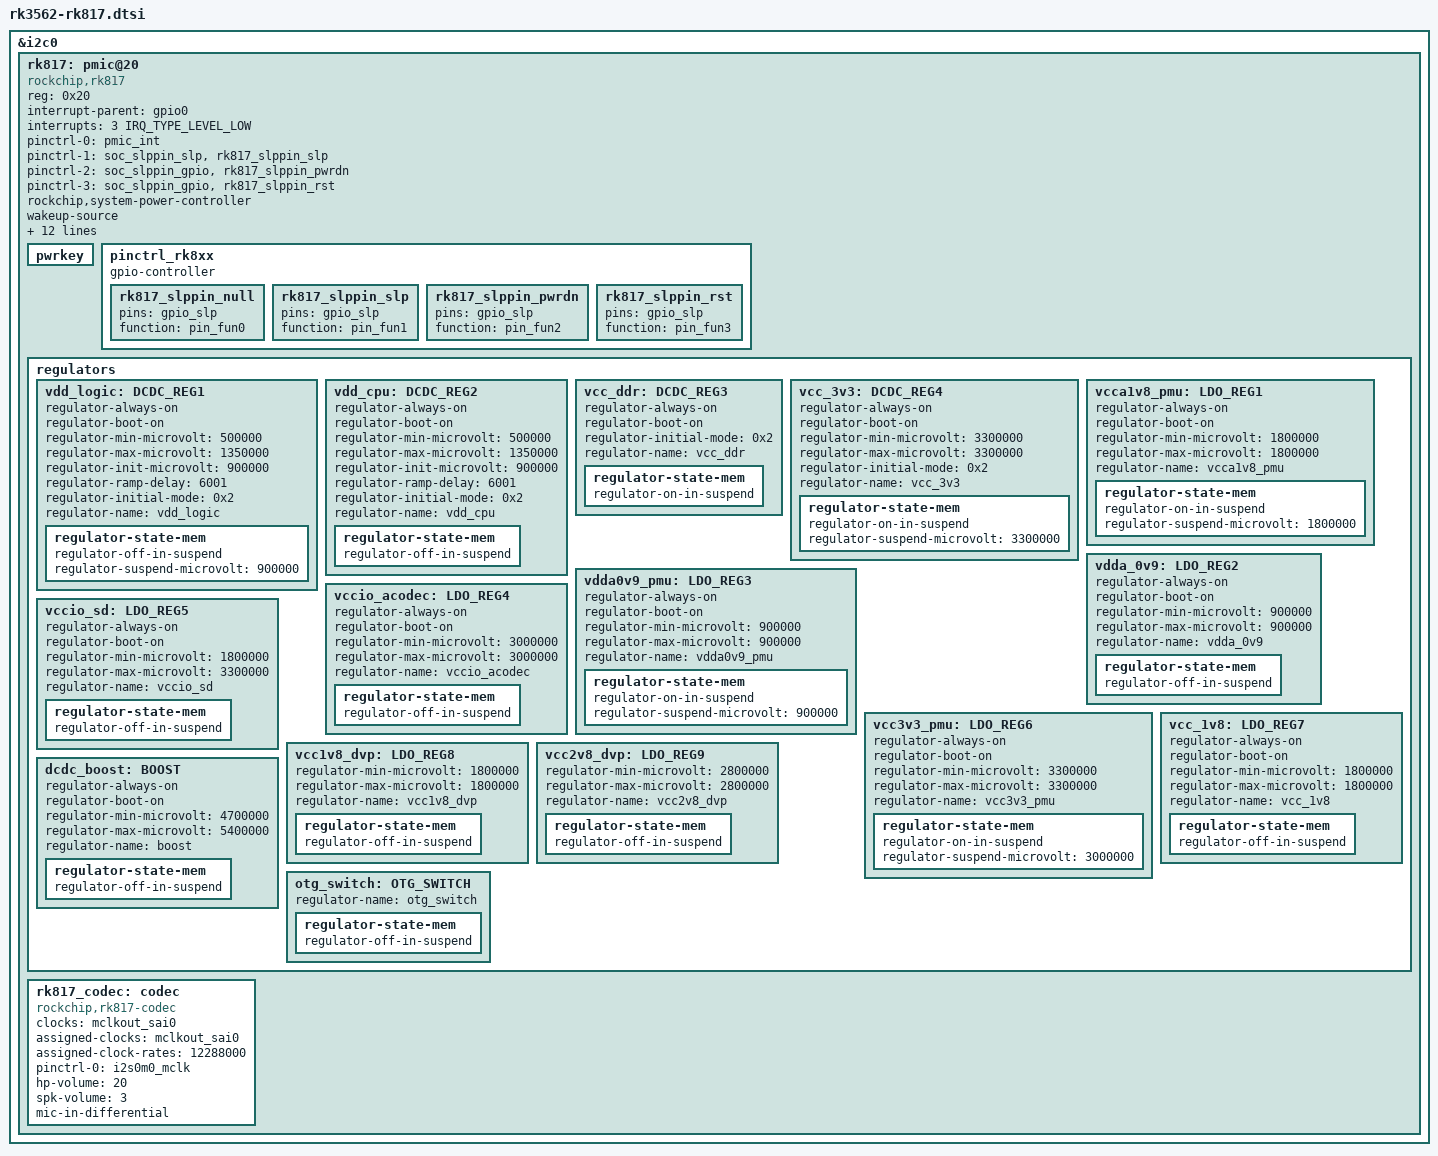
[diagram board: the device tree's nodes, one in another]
// SPDX-License-Identifier: (GPL-2.0+ OR MIT)
/*
 * Copyright (c) 2022 Rockchip Electronics Co., Ltd.
 *
 */

#include <dt-bindings/gpio/gpio.h>
#include <dt-bindings/pinctrl/rockchip.h>

&i2c0 {
	status = "okay";

	rk817: pmic@20 {
		compatible = "rockchip,rk817";
		reg = <0x20>;
		interrupt-parent = <&gpio0>;
		interrupts = <3 IRQ_TYPE_LEVEL_LOW>;

		pinctrl-names = "default", "pmic-sleep",
			"pmic-power-off", "pmic-reset";
		pinctrl-0 = <&pmic_int>;
		pinctrl-1 = <&soc_slppin_slp>, <&rk817_slppin_slp>;
		pinctrl-2 = <&soc_slppin_gpio>, <&rk817_slppin_pwrdn>;
		pinctrl-3 = <&soc_slppin_gpio>, <&rk817_slppin_rst>;
		rockchip,system-power-controller;
		wakeup-source;
		#clock-cells = <1>;
		clock-output-names = "rk808-clkout1", "rk808-clkout2";
		/* 1: rst regs (default in codes), 0: rst the pmic */
		pmic-reset-func = <0>;
		vcc1-supply = <&vcc_sys>;
		vcc2-supply = <&vcc_sys>;
		vcc3-supply = <&vcc_sys>;
		vcc4-supply = <&vcc_sys>;
		vcc5-supply = <&vcc_sys>;
		vcc6-supply = <&vcc_sys>;
		vcc7-supply = <&vcc_sys>;
		vcc8-supply = <&vcc_sys>;
		vcc9-supply = <&dcdc_boost>;
		pwrkey {
			status = "okay";
		};

		pinctrl_rk8xx: pinctrl_rk8xx {
			gpio-controller;
			#gpio-cells = <2>;

			rk817_slppin_null: rk817_slppin_null {
				pins = "gpio_slp";
				function = "pin_fun0";
			};

			rk817_slppin_slp: rk817_slppin_slp {
				pins = "gpio_slp";
				function = "pin_fun1";
			};

			rk817_slppin_pwrdn: rk817_slppin_pwrdn {
				pins = "gpio_slp";
				function = "pin_fun2";
			};

			rk817_slppin_rst: rk817_slppin_rst {
				pins = "gpio_slp";
				function = "pin_fun3";
			};
		};

		regulators {
			vdd_logic: DCDC_REG1 {
				regulator-always-on;
				regulator-boot-on;
				regulator-min-microvolt = <500000>;
				regulator-max-microvolt = <1350000>;
				regulator-init-microvolt = <900000>;
				regulator-ramp-delay = <6001>;
				regulator-initial-mode = <0x2>;
				regulator-name = "vdd_logic";
				regulator-state-mem {
					regulator-off-in-suspend;
					regulator-suspend-microvolt = <900000>;
				};
			};

			vdd_cpu: DCDC_REG2 {
				regulator-always-on;
				regulator-boot-on;
				regulator-min-microvolt = <500000>;
				regulator-max-microvolt = <1350000>;
				regulator-init-microvolt = <900000>;
				regulator-ramp-delay = <6001>;
				regulator-initial-mode = <0x2>;
				regulator-name = "vdd_cpu";
				regulator-state-mem {
					regulator-off-in-suspend;
				};
			};

			vcc_ddr: DCDC_REG3 {
				regulator-always-on;
				regulator-boot-on;
				regulator-initial-mode = <0x2>;
				regulator-name = "vcc_ddr";
				regulator-state-mem {
					regulator-on-in-suspend;
				};
			};

			vcc_3v3: DCDC_REG4 {
				regulator-always-on;
				regulator-boot-on;
				regulator-min-microvolt = <3300000>;
				regulator-max-microvolt = <3300000>;
				regulator-initial-mode = <0x2>;
				regulator-name = "vcc_3v3";
				regulator-state-mem {
					regulator-on-in-suspend;
					regulator-suspend-microvolt = <3300000>;
				};
			};

			vcca1v8_pmu: LDO_REG1 {
				regulator-always-on;
				regulator-boot-on;
				regulator-min-microvolt = <1800000>;
				regulator-max-microvolt = <1800000>;
				regulator-name = "vcca1v8_pmu";
				regulator-state-mem {
				regulator-on-in-suspend;
					regulator-suspend-microvolt = <1800000>;
				};
			};

			vdda_0v9: LDO_REG2 {
				regulator-always-on;
				regulator-boot-on;
				regulator-min-microvolt = <900000>;
				regulator-max-microvolt = <900000>;
				regulator-name = "vdda_0v9";
				regulator-state-mem {
					regulator-off-in-suspend;
				};
			};

			vdda0v9_pmu: LDO_REG3 {
				regulator-always-on;
				regulator-boot-on;
				regulator-min-microvolt = <900000>;
				regulator-max-microvolt = <900000>;
				regulator-name = "vdda0v9_pmu";
				regulator-state-mem {
				regulator-on-in-suspend;
					regulator-suspend-microvolt = <900000>;
				};
			};

			vccio_acodec: LDO_REG4 {
				regulator-always-on;
				regulator-boot-on;
				regulator-min-microvolt = <3000000>;
				regulator-max-microvolt = <3000000>;
				regulator-name = "vccio_acodec";
				regulator-state-mem {
					regulator-off-in-suspend;
				};
			};

			vccio_sd: LDO_REG5 {
				regulator-always-on;
				regulator-boot-on;
				regulator-min-microvolt = <1800000>;
				regulator-max-microvolt = <3300000>;
				regulator-name = "vccio_sd";
				regulator-state-mem {
					regulator-off-in-suspend;
				};
			};

			vcc3v3_pmu: LDO_REG6 {
				regulator-always-on;
				regulator-boot-on;
				regulator-min-microvolt = <3300000>;
				regulator-max-microvolt = <3300000>;
				regulator-name = "vcc3v3_pmu";
				regulator-state-mem {
					regulator-on-in-suspend;
					regulator-suspend-microvolt = <3000000>;
				};
			};

			vcc_1v8: LDO_REG7 {
				regulator-always-on;
				regulator-boot-on;
				regulator-min-microvolt = <1800000>;
				regulator-max-microvolt = <1800000>;
				regulator-name = "vcc_1v8";
				regulator-state-mem {
					regulator-off-in-suspend;
				};
			};

			vcc1v8_dvp: LDO_REG8 {
				regulator-min-microvolt = <1800000>;
				regulator-max-microvolt = <1800000>;
				regulator-name = "vcc1v8_dvp";
				regulator-state-mem {
					regulator-off-in-suspend;
				};
			};

			vcc2v8_dvp: LDO_REG9 {
				regulator-min-microvolt = <2800000>;
				regulator-max-microvolt = <2800000>;
				regulator-name = "vcc2v8_dvp";
				regulator-state-mem {
					regulator-off-in-suspend;
				};
			};

			dcdc_boost: BOOST {
				regulator-always-on;
				regulator-boot-on;
				regulator-min-microvolt = <4700000>;
				regulator-max-microvolt = <5400000>;
				regulator-name = "boost";
				regulator-state-mem {
					regulator-off-in-suspend;
				};
			};

			otg_switch: OTG_SWITCH {
				regulator-name = "otg_switch";
				regulator-state-mem {
					regulator-off-in-suspend;
				};
			};
		};

		rk817_codec: codec {
			#sound-dai-cells = <0>;
			compatible = "rockchip,rk817-codec";
			clocks = <&mclkout_sai0>;
			clock-names = "mclk";
			assigned-clocks = <&mclkout_sai0>;
			assigned-clock-rates = <12288000>;
			pinctrl-names = "default";
			pinctrl-0 = <&i2s0m0_mclk>;
			hp-volume = <20>;
			spk-volume = <3>;
			mic-in-differential;
			status = "okay";
		};
	};
};
